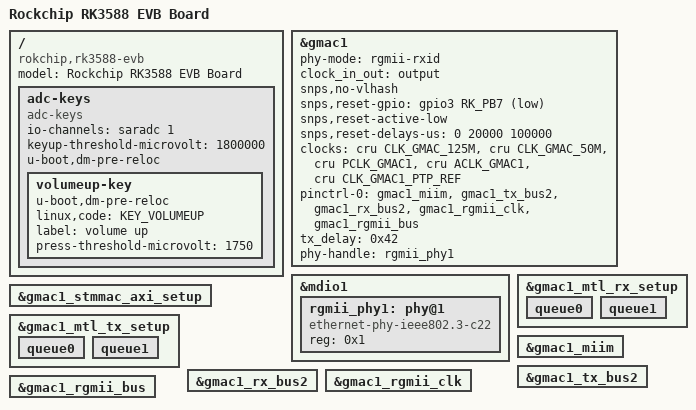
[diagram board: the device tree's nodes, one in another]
/*
 * SPDX-License-Identifier:     GPL-2.0+
 *
 * (C) Copyright 2020 Rockchip Electronics Co., Ltd
 */

/dts-v1/;
#include "rk3588.dtsi"
#include "rk3588-u-boot.dtsi"
#include <dt-bindings/input/input.h>

/ {
	model = "Rockchip RK3588 EVB Board";
	compatible = "rokchip,rk3588-evb", "rockchip,rk3588";

	adc-keys {
		compatible = "adc-keys";
		io-channels = <&saradc 1>;
		io-channel-names = "buttons";
		keyup-threshold-microvolt = <1800000>;
		u-boot,dm-pre-reloc;
		status = "okay";

		volumeup-key {
			u-boot,dm-pre-reloc;
			linux,code = <KEY_VOLUMEUP>;
			label = "volume up";
			press-threshold-microvolt = <1750>;
		};
	};
};

&gmac1 {
	u-boot,dm-spl;
	/* Use rgmii-rxid mode to disable rx delay inside Soc */
	phy-mode = "rgmii-rxid";
	clock_in_out = "output";

	snps,no-vlhash;
	snps,reset-gpio = <&gpio3 RK_PB7 GPIO_ACTIVE_LOW>;
	snps,reset-active-low;
	/* Reset time is 20ms, 100ms for rtl8211f */
	snps,reset-delays-us = <0 20000 100000>;

	clocks = <&cru CLK_GMAC_125M>, <&cru CLK_GMAC_50M>,
			<&cru PCLK_GMAC1>, <&cru ACLK_GMAC1>,
			<&cru CLK_GMAC1_PTP_REF>;
	clock-names = "stmmaceth", "clk_mac_ref",
				"pclk_mac", "aclk_mac",
				"ptp_ref";

	pinctrl-names = "default";
	pinctrl-0 = <&gmac1_miim
		     &gmac1_tx_bus2
		     &gmac1_rx_bus2
		     &gmac1_rgmii_clk
		     &gmac1_rgmii_bus>;

	tx_delay = <0x42>;
	/* rx_delay = <0x4f>; */

	phy-handle = <&rgmii_phy1>;
	status = "okay";
};

&mdio1 {
	u-boot,dm-spl;
	rgmii_phy1: phy@1 {
		u-boot,dm-spl;
		compatible = "ethernet-phy-ieee802.3-c22";
		reg = <0x1>;
	};
};

&gmac1_stmmac_axi_setup {
	u-boot,dm-spl;
};

&gmac1_mtl_rx_setup {
	u-boot,dm-spl;
	queue0 {u-boot,dm-spl;};
	queue1 {u-boot,dm-spl;};
};

&gmac1_mtl_tx_setup {
	u-boot,dm-spl;
	queue0 {u-boot,dm-spl;};
	queue1 {u-boot,dm-spl;};
};

&gmac1_miim {u-boot,dm-spl;};
&gmac1_tx_bus2 {u-boot,dm-spl;};
&gmac1_rx_bus2 {u-boot,dm-spl;};
&gmac1_rgmii_clk {u-boot,dm-spl;};
&gmac1_rgmii_bus {u-boot,dm-spl;};
